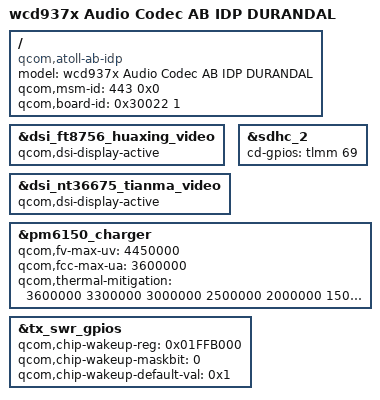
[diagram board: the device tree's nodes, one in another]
/* Copyright (c) 2019, The Linux Foundation. All rights reserved.
 *
 * This program is free software; you can redistribute it and/or modify
 * it under the terms of the GNU General Public License version 2 and
 * only version 2 as published by the Free Software Foundation.
 *
 * This program is distributed in the hope that it will be useful,
 * but WITHOUT ANY WARRANTY; without even the implied warranty of
 * MERCHANTABILITY or FITNESS FOR A PARTICULAR PURPOSE.  See the
 * GNU General Public License for more details.
 */

/dts-v1/;
/plugin/;

#include <dt-bindings/interrupt-controller/arm-gic.h>

#include "atoll-idp.dtsi"
#include "atoll-wcd937x-idp-audio-overlay.dtsi"
#include "custd-atoll-camera-sensor-idp.dtsi"

/ {
	model = "wcd937x Audio Codec AB IDP DURANDAL";
	compatible = "qcom,atoll-ab-idp", "qcom,atoll-ab", "qcom,idp";
	qcom,msm-id = <443 0x0>;
	qcom,board-id = <0x30022 1>;
};

&dsi_ft8756_huaxing_video {
	qcom,dsi-display-active;
};
&dsi_nt36675_tianma_video {
	qcom,dsi-display-active;
};
&sdhc_2 {
	cd-gpios = <&tlmm 69 0>;
};

&pm6150_charger {
	qcom,fv-max-uv = <4450000>;
	qcom,fcc-max-ua = <3600000>;
	qcom,thermal-mitigation = <3600000 3300000 3000000 2500000 2000000 1500000 1000000 500000>;
};

&tx_swr_gpios {
	qcom,chip-wakeup-reg = <0x01FFB000>;
	qcom,chip-wakeup-maskbit = <0>;
	qcom,chip-wakeup-default-val = <0x1>;
};
